# MK53DZ10 register map
Vendor: Freescale Semiconductor, Inc.; Series: Kinetis_K; File version: 1.6
CPU: CM4 r0p1, little endian, no MPU, no FPU, VTOR, 4 interrupt priority bits
Registers are 32-bit, read-write, reset 0x0 unless marked. A register's access mark holds for its fields unless they carry their own. Offsets are from the block's base; [hi:lo] are bit positions; {n}, {i} and the like mark numbered series; 'fields as' and 'values as' point back to an identical list.

## SIM — System Integration Module
Base 0x40047000; register names take the prefix SIM_
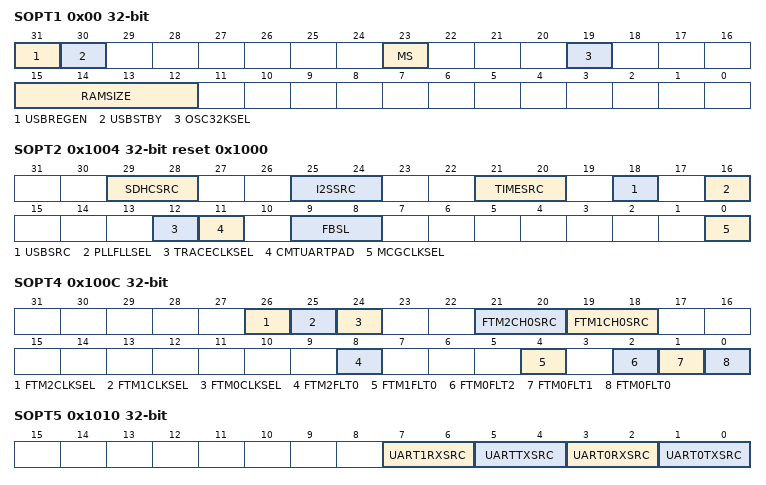
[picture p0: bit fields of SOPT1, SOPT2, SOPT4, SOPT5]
0x00 SOPT1 reset not defined — System Options Register 1
  [31] USBREGEN — USB voltage regulator enable
    0=USB voltage regulator is disabled; 1=USB voltage regulator is enabled
  [30] USBSTBY — USB voltage regulator in standby mode
    0=USB voltage regulator not in standby; 1=USB voltage regulator in standby
  [23] MS ro — EzPort chip select pin state
  [19] OSC32KSEL — 32K oscillator clock select
    0=System oscillator (OSC32KCLK); 1=RTC oscillator
  [15:12] RAMSIZE ro
    {v}=Undefined (v=0..4); 5=32 KBytes; 6=Undefined; 7=64 KBytes; 8=96 KBytes; 9=128 KBytes; {v}=Undefined (v=10..15)
0x1004 SOPT2 reset 0x1000 — System Options Register 2
  [29:28] SDHCSRC — SDHC clock source select
    0=Core/system clock; 1=MCGPLLCLK/MCGFLLCLK clock; 2=OSCERCLK clock; 3=External bypass clock (SDHC0_CLKIN)
  [25:24] I2SSRC — I2S master clock source select
    0=Core/system clock divided by the I2S fractional clock divider. See the SIM_CLKDIV2[I2SFRAC, I2SDIV] descriptions.; 1=MCGPLLCLK/MCGFLLCLK clock divided by the I2S fractional clock divider. See the SIM_CLKDIV2[I2SFRAC, I2SDIV] descriptions.; 2=OSCERCLK clock; 3=External bypass clock (I2S0_CLKIN)
  [21:20] TIMESRC — IEEE 1588 timestamp clock source select
    0=Core/system clock; 1=MCGPLLCLK/MCGFLLCLK clock; 2=OSCERCLK clock; 3=External bypass clock (ENET_1588_CLKIN)
  [18] USBSRC — USB clock source select
    0=External bypass clock (USB_CLKIN); 1=MCGPLLCLK/MCGFLLCLK clock divided by the USB fractional divider. See the SIM_CLKDIV2[USBFRAC, USBDIV] descriptions.
  [16] PLLFLLSEL — PLL/FLL clock select
    0=MCGFLLCLK clock; 1=MCGPLLCLK clock
  [12] TRACECLKSEL — Debug trace clock select
    0=MCGOUTCLK; 1=Core/system clock
  [11] CMTUARTPAD — CMT/UART pad drive strength
    0=Single-pad drive strength for CMT IRO or UART0_TXD; 1=Dual-pad drive strength for CMT IRO or UART0_TXD
  [9:8] FBSL — FlexBus security level
    0=All off-chip accesses (instruction and data) via the FlexBus are disallowed; 1=All off-chip accesses (instruction and data) via the FlexBus are disallowed; 2=Off-chip instruction accesses are disallowed. Data accesses are allowed.; 3=Off-chip instruction accesses and data accesses are allowed
  [0] MCGCLKSEL — MCG clock select
    0=System oscillator (OSCCLK); 1=32 kHz RTC oscillator
0x100C SOPT4 — System Options Register 4
  [26] FTM2CLKSEL — FlexTimer 2 External Clock Pin Select
    0=FTM2 external clock driven by FTM_CLK0 pin; 1=FTM2 external clock driven by FTM_CLK1 pin
  [25] FTM1CLKSEL — FTM1 External Clock Pin Select
    0=FTM_CLK0 pin; 1=FTM_CLK1 pin
  [24] FTM0CLKSEL — FlexTimer 0 External Clock Pin Select
    0=FTM_CLK0 pin; 1=FTM_CLK1 pin
  [21:20] FTM2CH0SRC — FTM2 channel 0 input capture source select
    0=FTM2_CH0 signal; 1=CMP0 output; 2=CMP1 output
  [19:18] FTM1CH0SRC — FTM1 channel 0 input capture source select
    0=FTM1_CH0 signal; 1=CMP0 output; 2=CMP1 output
  [8] FTM2FLT0 — FTM2 Fault 0 Select
    0=FTM2_FLT0 pin; 1=CMP0 out
  [4] FTM1FLT0 — FTM1 Fault 0 Select
    0=FTM1_FLT0 pin; 1=CMP0 out
  [2] FTM0FLT2 — FTM0 Fault 2 Select
    0=FTM0_FLT2 pin; 1=CMP2 out
  [1] FTM0FLT1 — FTM0 Fault 1 Select
    0=FTM0_FLT1 pin; 1=CMP1 out
  [0] FTM0FLT0 — FTM0 Fault 0 Select
    0=FTM0_FLT0 pin; 1=CMP0 out
0x1010 SOPT5 — System Options Register 5
  [7:6] UART1RXSRC — UART 1 receive data source select
    0=UART1_RX pin; 1=CMP0; 2=CMP1
  [5:4] UARTTXSRC — UART 1 transmit data source select
    0=UART1_TX pin; 1=UART1_TX pin modulated with FTM1 channel 0 output; 2=UART1_TX pin modulated with FTM2 channel 0 output
  [3:2] UART0RXSRC — UART 0 receive data source select
    0=UART0_RX pin; 1=CMP0; 2=CMP1
  [1:0] UART0TXSRC — UART 0 transmit data source select
    0=UART0_TX pin; 1=UART0_TX pin modulated with FTM1 channel 0 output; 2=UART0_TX pin modulated with FTM2 channel 0 output
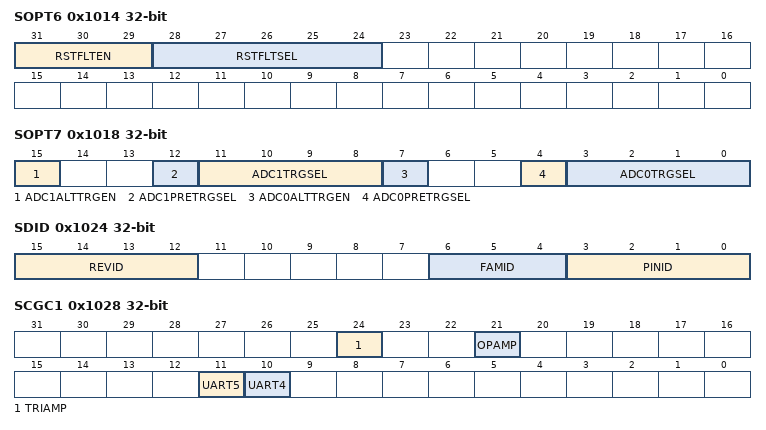
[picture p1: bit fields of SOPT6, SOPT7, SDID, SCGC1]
0x1014 SOPT6 — System Options Register 6
  [31:29] RSTFLTEN — Reset pin filter enable
    0=All filtering disabled; 1=Bus clock filter enabled in normal operation. LPO clock filter enabled in stop mode.; 2=LPO clock filter enabled; 3=Bus clock filter enabled in normal operation. All filtering disabled in stop mode.; 4=LPO clock filter enabled in normal operation. All filtering disabled in stop mode.
  [28:24] RSTFLTSEL — Reset pin filter select
0x1018 SOPT7 — System Options Register 7
  [15] ADC1ALTTRGEN — ADC1 alternate trigger enable
    0=PDB trigger selected for ADC1; 1=Alternate trigger selected for ADC1 as defined by ADC1TRGSEL
  [12] ADC1PRETRGSEL — ADC1 pre-trigger select
    0=Pre-trigger A selected for ADC1; 1=Pre-trigger B selected for ADC1
  [11:8] ADC1TRGSEL — ADC1 trigger select
    0=PDB external trigger pin input (PDB0_EXTRG); 1=High speed comparator 0 output; 2=High speed comparator 1 output; 3=High speed comparator 2 output; {v}=PIT trigger {v-4} (v=4..7); 8=FTM0 trigger; 9=FTM1 trigger; 10=FTM2 trigger; 12=RTC alarm; 13=RTC seconds; 14=Low-power timer trigger
  [7] ADC0ALTTRGEN — ADC0 alternate trigger enable
    0=PDB trigger selected for ADC0; 1=Alternate trigger selected for ADC0
  [4] ADC0PRETRGSEL — ADC0 pretrigger select
    0=Pre-trigger A; 1=Pre-trigger B
  [3:0] ADC0TRGSEL — ADC0 trigger select
    values as ADC1TRGSEL
0x1024 SDID ro reset not defined — System Device Identification Register
  [15:12] REVID — Device revision number
  [6:4] FAMID — Kinetis family identification
    0=K10; 1=K20; 2=K30; 3=K40; 4=K60; 5=K70; 6=K50 and K52; 7=K51 and K53
  [3:0] PINID — Pincount identification
    2=32-pin; 4=48-pin; 5=64-pin; 6=80-pin; 7=81-pin; 8=100-pin; 9=121-pin; 10=144-pin; 12=196-pin; 14=256-pin
0x1028 SCGC1 — System Clock Gating Control Register 1
  [all] fields
    0=Clock disabled; 1=Clock enabled
  [24] TRIAMP — TRIAMP Clock Gate Control
  [21] OPAMP — OPAMP Clock Gate Control
  [11] UART5 — UART5 Clock Gate Control
  [10] UART4 — UART4 Clock Gate Control
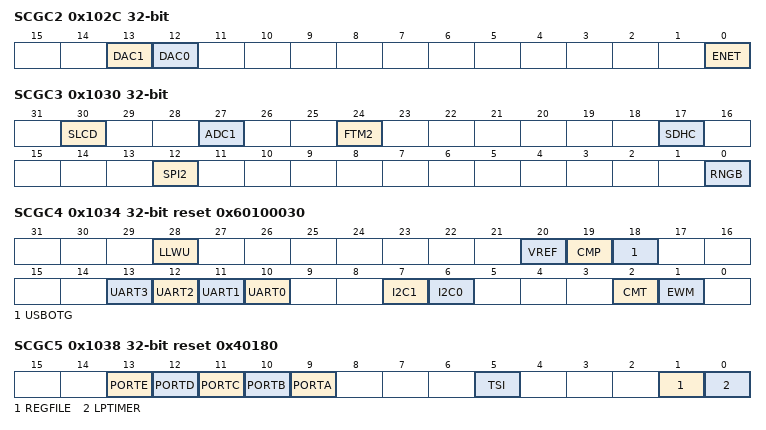
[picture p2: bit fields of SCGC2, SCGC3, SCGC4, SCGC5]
0x102C SCGC2 — System Clock Gating Control Register 2
  [all] fields
    0=Clock disabled; 1=Clock enabled
  [13] DAC1 — DAC1 Clock Gate Control
  [12] DAC0 — DAC0 Clock Gate Control
  [0] ENET — ENET Clock Gate Control
0x1030 SCGC3 — System Clock Gating Control Register 3
  [all] fields
    0=Clock disabled; 1=Clock enabled
  [30] SLCD — Segment LCD Clock Gate Control
  [27] ADC1 — ADC1 Clock Gate Control
  [24] FTM2 — FTM2 Clock Gate Control
  [17] SDHC — SDHC Clock Gate Control
  [12] SPI2 — SPI2 Clock Gate Control
  [0] RNGB — RNGB Clock Gate Control
0x1034 SCGC4 reset 0x60100030 — System Clock Gating Control Register 4
  [all] fields
    0=Clock disabled; 1=Clock enabled
  [28] LLWU — LLWU Clock Gate Control
  [20] VREF — VREF Clock Gate Control
  [19] CMP — Comparator Clock Gate Control
  [18] USBOTG — USB Clock Gate Control
  [n+10] UART{n} (n=0..3) — UART{n} Clock Gate Control
  [7] I2C1 — I2C1 Clock Gate Control
  [6] I2C0 — I2C0 Clock Gate Control
  [2] CMT — CMT Clock Gate Control
  [1] EWM — EWM Clock Gate Control
0x1038 SCGC5 reset 0x40180 — System Clock Gating Control Register 5
  [all] fields
    0=Clock disabled; 1=Clock enabled
  [13] PORTE — Port E Clock Gate Control
  [12] PORTD — Port D Clock Gate Control
  [11] PORTC — Port C Clock Gate Control
  [10] PORTB — Port B Clock Gate Control
  [9] PORTA — Port A Clock Gate Control
  [5] TSI — TSI Clock Gate Control
  [1] REGFILE — Register File Clock Gate Control
  [0] LPTIMER — Low Power Timer Clock Gate Control
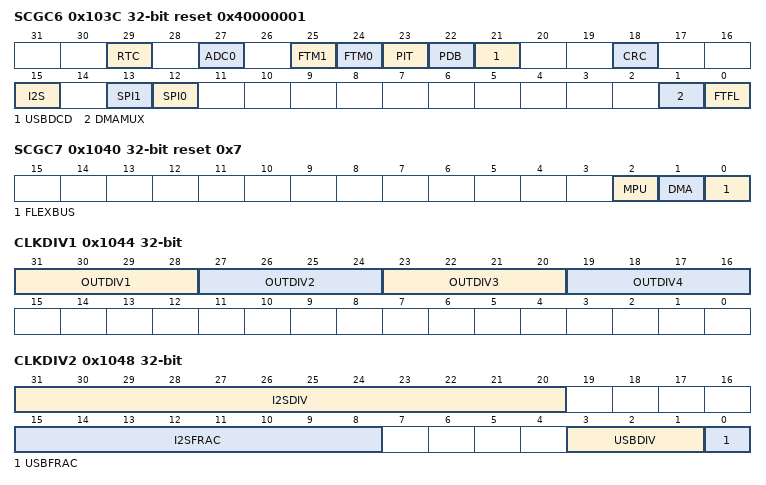
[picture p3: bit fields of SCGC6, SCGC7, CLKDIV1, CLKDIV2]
0x103C SCGC6 reset 0x40000001 — System Clock Gating Control Register 6
  [all] fields
    0=Clock disabled; 1=Clock enabled
  [29] RTC — RTC Clock Gate Control
  [27] ADC0 — ADC0 Clock Gate Control
  [25] FTM1 — FTM1 Clock Gate Control
  [24] FTM0 — FTM0 Clock Gate Control
  [23] PIT — PIT Clock Gate Control
  [22] PDB — PDB Clock Gate Control
  [21] USBDCD — USB DCD Clock Gate Control
  [18] CRC — CRC Clock Gate Control
  [15] I2S — I2S Clock Gate Control
  [13] SPI1 — SPI1 Clock Gate Control
  [12] SPI0 — SPI0 Clock Gate Control
  [1] DMAMUX — DMA Mux Clock Gate Control
  [0] FTFL — Flash Memory Clock Gate Control
0x1040 SCGC7 reset 0x7 — System Clock Gating Control Register 7
  [all] fields
    0=Clock disabled; 1=Clock enabled
  [2] MPU — MPU Clock Gate Control
  [1] DMA — DMA Clock Gate Control
  [0] FLEXBUS — FlexBus Clock Gate Control
0x1044 CLKDIV1 reset not defined — System Clock Divider Register 1
  [all] fields
    {v}=Divide-by-{v+1} (v=0..15)
  [35-4n:32-4n] OUTDIV{n} (n=1..4) — Clock {n} output divider value
0x1048 CLKDIV2 — System Clock Divider Register 2
  [31:20] I2SDIV — I2S clock divider value
  [15:8] I2SFRAC — I2S clock divider fraction
  [3:1] USBDIV — USB clock divider divisor
  [0] USBFRAC — USB clock divider fraction
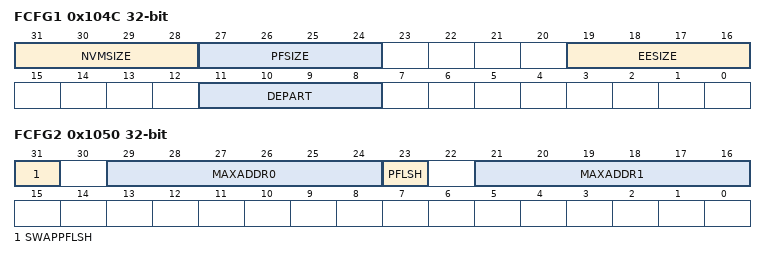
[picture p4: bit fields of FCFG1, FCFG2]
0x104C FCFG1 ro reset not defined — Flash Configuration Register 1
  [31:28] NVMSIZE — FlexNVM size
    0=0 KB of FlexNVM; 7=128 KB of FlexNVM, 16 KB protection region; 9=256 KB of FlexNVM, 32 KB protection region; 15=256 KB of FlexNVM, 32 KB protection region
  [27:24] PFSIZE — Program flash size
    7=128 KB of program flash memory, 4 KB protection region; 9=256 KB of program flash memory, 8 KB protection region; 11=512 KB of program flash memory, 16 KB protection region; 15=For devices with FlexNVM (SIM_FCFG2[PFLSH]=0): 256 KB of program flash, 8 KB protection region. For devices without FlexNVM (SIM_FCFG2[PFLSH]=1): 512 KB of program flash memory, 16 KB protection region
  [19:16] EESIZE — EEPROM size
    2=4 KB; 3=2 KB; 4=1 KB; 5=512 Bytes; 6=256 Bytes; 7=128 Bytes; 8=64 Bytes; 9=32 Bytes; 15=0 Bytes
  [11:8] DEPART — FlexNVM partition
0x1050 FCFG2 ro reset not defined — Flash Configuration Register 2
  [31] SWAPPFLSH — Swap program flash
    0=Swap is not active; 1=Swap is active
  [29:24] MAXADDR0 — Max address block 0
  [23] PFLSH — Program flash
    0=For devices with FlexNVM: Physical flash block 1 is used as FlexNVM For devices without FlexNVM: Reserved; 1=Physical flash block 1 is used as program flash
  [21:16] MAXADDR1 — Max address block 1
0x1054 UIDH ro reset not defined — Unique Identification Register High
  [31:0] UID — Unique Identification
0x1058 UIDMH ro reset not defined — Unique Identification Register Mid-High
  [31:0] UID — Unique Identification
0x105C UIDML ro reset not defined — Unique Identification Register Mid Low
  [31:0] UID — Unique Identification
0x1060 UIDL ro reset not defined — Unique Identification Register Low
  [31:0] UID — Unique Identification

## Notices in the file
Redistribution and use in source and binary forms, with or without modification,
are permitted provided that the following conditions are met:
o Redistributions of source code must retain the above copyright notice, this list
of conditions and the following disclaimer.
o Redistributions in binary form must reproduce the above copyright notice, this
list of conditions and the following disclaimer in the documentation and/or
other materials provided with the distribution.
o Neither the name of Freescale Semiconductor, Inc. nor the names of its
contributors may be used to endorse or promote products derived from this
software without specific prior written permission.
THIS SOFTWARE IS PROVIDED BY THE COPYRIGHT HOLDERS AND CONTRIBUTORS "AS IS" AND
ANY EXPRESS OR IMPLIED WARRANTIES, INCLUDING, BUT NOT LIMITED TO, THE IMPLIED
WARRANTIES OF MERCHANTABILITY AND FITNESS FOR A PARTICULAR PURPOSE ARE
DISCLAIMED. IN NO EVENT SHALL THE COPYRIGHT HOLDER OR CONTRIBUTORS BE LIABLE FOR
ANY DIRECT, INDIRECT, INCIDENTAL, SPECIAL, EXEMPLARY, OR CONSEQUENTIAL DAMAGES
(INCLUDING, BUT NOT LIMITED TO, PROCUREMENT OF SUBSTITUTE GOODS OR SERVICES;
LOSS OF USE, DATA, OR PROFITS; OR BUSINESS INTERRUPTION) HOWEVER CAUSED AND ON
ANY THEORY OF LIABILITY, WHETHER IN CONTRACT, STRICT LIABILITY, OR TORT
(INCLUDING NEGLIGENCE OR OTHERWISE) ARISING IN ANY WAY OUT OF THE USE OF THIS
SOFTWARE, EVEN IF ADVISED OF THE POSSIBILITY OF SUCH DAMAGE.
